# ESP32-C5 register map
Vendor: ESPRESSIF SYSTEMS (SHANGHAI) CO., LTD.; Series: ESP32 C-Series; File version: 1
CPU: RV32IMAC r0p0, little endian, no MPU, no FPU, 0 interrupt priority bits
Address unit: 32 bits
Registers are 32-bit, read-write, reset 0x0 unless marked. A register's access mark holds for its fields unless they carry their own. Offsets are from the block's base; [hi:lo] are bit positions; {n}, {i} and the like mark numbered series.

## PVT — PVT Peripheral
Base 0x60019000
{0x0+4i} PMUP_BITMAP_HIGH{i} (i=0..4) — select valid pvt channel
  [31:0] PUMP_BITMAP_HIGH{i} — select valid high channel{i}
{0x14+4i} PMUP_BITMAP_LOW{i} (i=0..4) — select valid pvt channel
  [31:0] PUMP_BITMAP_LOW{i} — select valid low channel{i}
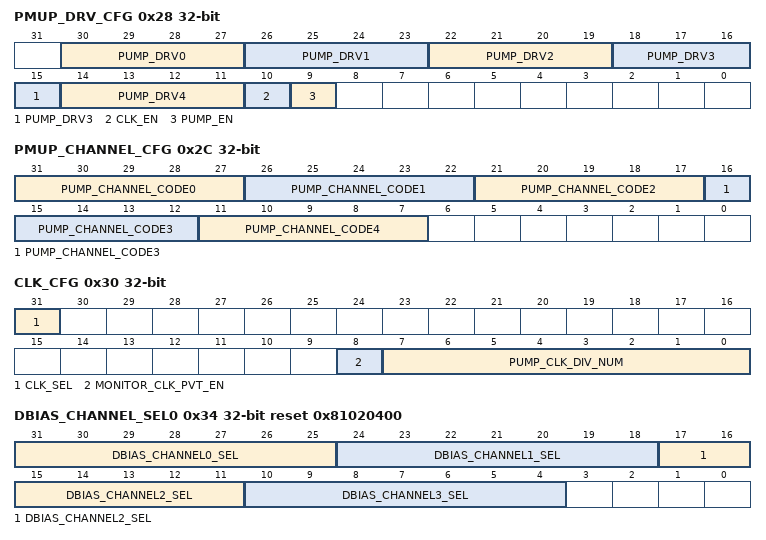
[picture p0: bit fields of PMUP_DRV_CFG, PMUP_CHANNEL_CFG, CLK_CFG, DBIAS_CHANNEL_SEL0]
0x28 PMUP_DRV_CFG — configure pump drv
  [30-4n:27-4n] PUMP_DRV{n} (n=0..4) — configure cmd{n} drv
  [10] CLK_EN — force register clken
  [9] PUMP_EN — configure pvt charge xpd
0x2C PMUP_CHANNEL_CFG — configure the code of valid pump channel code
  [31-5n:27-5n] PUMP_CHANNEL_CODE{n} (n=0..4) — configure cmd{n} code
0x30 CLK_CFG — configure pvt clk
  [31] CLK_SEL — select pvt clk
  [8] MONITOR_CLK_PVT_EN — needs field desc
  [7:0] PUMP_CLK_DIV_NUM — needs field desc
0x34 DBIAS_CHANNEL_SEL0 reset 0x81020400 — needs desc
  [31-7n:25-7n] DBIAS_CHANNEL{n}_SEL (n=0..3) — needs field desc
0x38 DBIAS_CHANNEL_SEL1 reset 0x80000000 — needs desc
  [31:25] DBIAS_CHANNEL4_SEL — needs field desc
{0x3C+4i} DBIAS_CHANNEL{i}_SEL (i=0..4) — needs desc
  [16:0] DBIAS_CHANNEL{i}_CFG — needs field desc
{0x50+4i} DBIAS_CMD{i} (i=0..4) — needs desc
  [16:0] DBIAS_CMD{i} — needs field desc
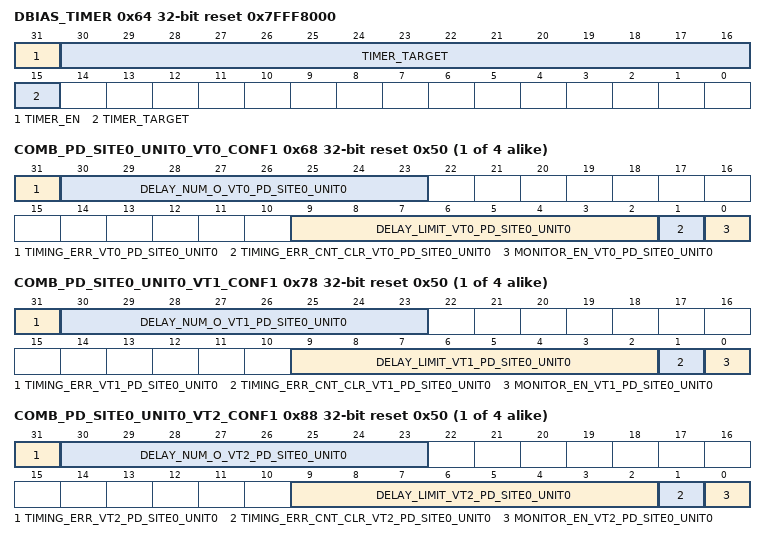
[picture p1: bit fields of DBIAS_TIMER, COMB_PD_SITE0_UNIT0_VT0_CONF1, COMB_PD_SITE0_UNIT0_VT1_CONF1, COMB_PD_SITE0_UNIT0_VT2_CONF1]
0x64 DBIAS_TIMER reset 0x7FFF8000 — needs desc
  [31] TIMER_EN — needs field desc
  [30:15] TIMER_TARGET — needs field desc
{0x68+4i} COMB_PD_SITE0_UNIT{i}_VT0_CONF1 ro reset 0x50 (i=0..3) — needs desc
  [31] TIMING_ERR_VT0_PD_SITE0_UNIT{i} — needs field desc
  [30:23] DELAY_NUM_O_VT0_PD_SITE0_UNIT{i} — needs field desc
  [9:2] DELAY_LIMIT_VT0_PD_SITE0_UNIT{i} — needs field desc
  [1] TIMING_ERR_CNT_CLR_VT0_PD_SITE0_UNIT{i} — needs field desc
  [0] MONITOR_EN_VT0_PD_SITE0_UNIT{i} — needs field desc
{0x78+4i} COMB_PD_SITE0_UNIT{i}_VT1_CONF1 ro reset 0x50 (i=0..3) — needs desc
  [31] TIMING_ERR_VT1_PD_SITE0_UNIT{i} — needs field desc
  [30:23] DELAY_NUM_O_VT1_PD_SITE0_UNIT{i} — needs field desc
  [9:2] DELAY_LIMIT_VT1_PD_SITE0_UNIT{i} — needs field desc
  [1] TIMING_ERR_CNT_CLR_VT1_PD_SITE0_UNIT{i} — needs field desc
  [0] MONITOR_EN_VT1_PD_SITE0_UNIT{i} — needs field desc
{0x88+4i} COMB_PD_SITE0_UNIT{i}_VT2_CONF1 ro reset 0x50 (i=0..3) — needs desc
  [31] TIMING_ERR_VT2_PD_SITE0_UNIT{i} — needs field desc
  [30:23] DELAY_NUM_O_VT2_PD_SITE0_UNIT{i} — needs field desc
  [9:2] DELAY_LIMIT_VT2_PD_SITE0_UNIT{i} — needs field desc
  [1] TIMING_ERR_CNT_CLR_VT2_PD_SITE0_UNIT{i} — needs field desc
  [0] MONITOR_EN_VT2_PD_SITE0_UNIT{i} — needs field desc
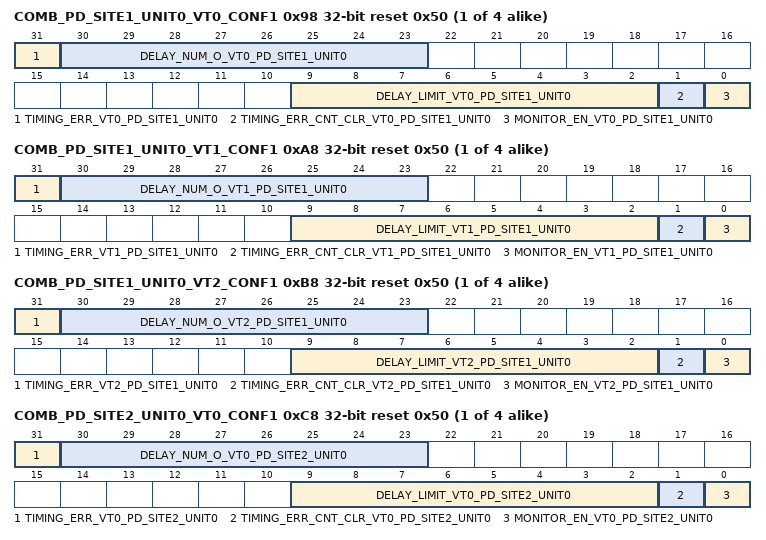
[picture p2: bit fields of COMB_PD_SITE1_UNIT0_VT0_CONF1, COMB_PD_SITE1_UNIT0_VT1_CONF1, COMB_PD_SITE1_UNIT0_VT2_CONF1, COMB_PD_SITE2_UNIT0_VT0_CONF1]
{0x98+4i} COMB_PD_SITE1_UNIT{i}_VT0_CONF1 ro reset 0x50 (i=0..3) — needs desc
  [31] TIMING_ERR_VT0_PD_SITE1_UNIT{i} — needs field desc
  [30:23] DELAY_NUM_O_VT0_PD_SITE1_UNIT{i} — needs field desc
  [9:2] DELAY_LIMIT_VT0_PD_SITE1_UNIT{i} — needs field desc
  [1] TIMING_ERR_CNT_CLR_VT0_PD_SITE1_UNIT{i} — needs field desc
  [0] MONITOR_EN_VT0_PD_SITE1_UNIT{i} — needs field desc
{0xA8+4i} COMB_PD_SITE1_UNIT{i}_VT1_CONF1 ro reset 0x50 (i=0..3) — needs desc
  [31] TIMING_ERR_VT1_PD_SITE1_UNIT{i} — needs field desc
  [30:23] DELAY_NUM_O_VT1_PD_SITE1_UNIT{i} — needs field desc
  [9:2] DELAY_LIMIT_VT1_PD_SITE1_UNIT{i} — needs field desc
  [1] TIMING_ERR_CNT_CLR_VT1_PD_SITE1_UNIT{i} — needs field desc
  [0] MONITOR_EN_VT1_PD_SITE1_UNIT{i} — needs field desc
{0xB8+4i} COMB_PD_SITE1_UNIT{i}_VT2_CONF1 ro reset 0x50 (i=0..3) — needs desc
  [31] TIMING_ERR_VT2_PD_SITE1_UNIT{i} — needs field desc
  [30:23] DELAY_NUM_O_VT2_PD_SITE1_UNIT{i} — needs field desc
  [9:2] DELAY_LIMIT_VT2_PD_SITE1_UNIT{i} — needs field desc
  [1] TIMING_ERR_CNT_CLR_VT2_PD_SITE1_UNIT{i} — needs field desc
  [0] MONITOR_EN_VT2_PD_SITE1_UNIT{i} — needs field desc
{0xC8+4i} COMB_PD_SITE2_UNIT{i}_VT0_CONF1 access per field reset 0x50 (i=0..3) — needs desc
  [31] TIMING_ERR_VT0_PD_SITE2_UNIT{i} ro — needs field desc
  [30:23] DELAY_NUM_O_VT0_PD_SITE2_UNIT{i} ro — needs field desc
  [9:2] DELAY_LIMIT_VT0_PD_SITE2_UNIT{i} rw — needs field desc
  [1] TIMING_ERR_CNT_CLR_VT0_PD_SITE2_UNIT{i} wo — needs field desc
  [0] MONITOR_EN_VT0_PD_SITE2_UNIT{i} rw — needs field desc
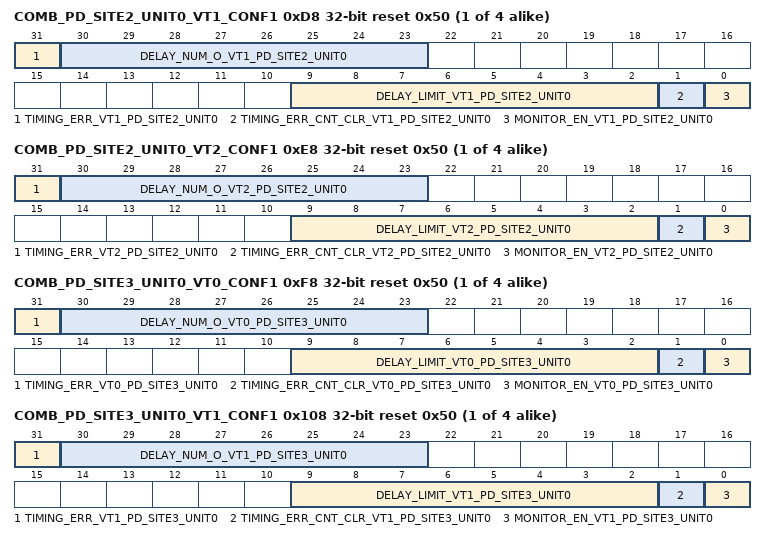
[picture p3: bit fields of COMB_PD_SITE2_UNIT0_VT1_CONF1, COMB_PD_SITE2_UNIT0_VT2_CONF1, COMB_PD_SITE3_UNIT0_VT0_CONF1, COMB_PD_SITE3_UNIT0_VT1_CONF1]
{0xD8+4i} COMB_PD_SITE2_UNIT{i}_VT1_CONF1 access per field reset 0x50 (i=0..3) — needs desc
  [31] TIMING_ERR_VT1_PD_SITE2_UNIT{i} ro — needs field desc
  [30:23] DELAY_NUM_O_VT1_PD_SITE2_UNIT{i} ro — needs field desc
  [9:2] DELAY_LIMIT_VT1_PD_SITE2_UNIT{i} rw — needs field desc
  [1] TIMING_ERR_CNT_CLR_VT1_PD_SITE2_UNIT{i} wo — needs field desc
  [0] MONITOR_EN_VT1_PD_SITE2_UNIT{i} rw — needs field desc
{0xE8+4i} COMB_PD_SITE2_UNIT{i}_VT2_CONF1 access per field reset 0x50 (i=0..3) — needs desc
  [31] TIMING_ERR_VT2_PD_SITE2_UNIT{i} ro — needs field desc
  [30:23] DELAY_NUM_O_VT2_PD_SITE2_UNIT{i} ro — needs field desc
  [9:2] DELAY_LIMIT_VT2_PD_SITE2_UNIT{i} rw — needs field desc
  [1] TIMING_ERR_CNT_CLR_VT2_PD_SITE2_UNIT{i} wo — needs field desc
  [0] MONITOR_EN_VT2_PD_SITE2_UNIT{i} rw — needs field desc
{0xF8+4i} COMB_PD_SITE3_UNIT{i}_VT0_CONF1 ro reset 0x50 (i=0..3) — needs desc
  [31] TIMING_ERR_VT0_PD_SITE3_UNIT{i} — needs field desc
  [30:23] DELAY_NUM_O_VT0_PD_SITE3_UNIT{i} — needs field desc
  [9:2] DELAY_LIMIT_VT0_PD_SITE3_UNIT{i} — needs field desc
  [1] TIMING_ERR_CNT_CLR_VT0_PD_SITE3_UNIT{i} — needs field desc
  [0] MONITOR_EN_VT0_PD_SITE3_UNIT{i} — needs field desc
{0x108+4i} COMB_PD_SITE3_UNIT{i}_VT1_CONF1 ro reset 0x50 (i=0..3) — needs desc
  [31] TIMING_ERR_VT1_PD_SITE3_UNIT{i} — needs field desc
  [30:23] DELAY_NUM_O_VT1_PD_SITE3_UNIT{i} — needs field desc
  [9:2] DELAY_LIMIT_VT1_PD_SITE3_UNIT{i} — needs field desc
  [1] TIMING_ERR_CNT_CLR_VT1_PD_SITE3_UNIT{i} — needs field desc
  [0] MONITOR_EN_VT1_PD_SITE3_UNIT{i} — needs field desc
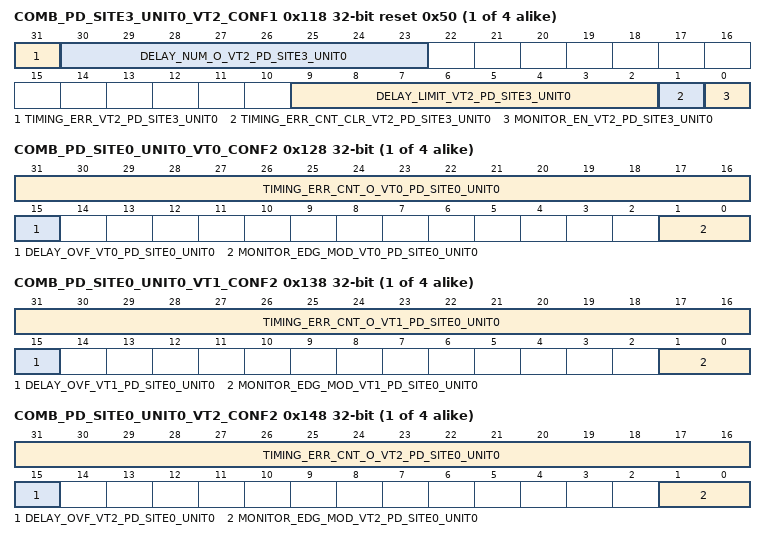
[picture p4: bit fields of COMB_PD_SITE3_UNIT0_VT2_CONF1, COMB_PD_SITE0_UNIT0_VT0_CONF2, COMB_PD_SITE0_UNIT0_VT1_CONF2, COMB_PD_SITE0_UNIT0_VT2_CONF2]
{0x118+4i} COMB_PD_SITE3_UNIT{i}_VT2_CONF1 ro reset 0x50 (i=0..3) — needs desc
  [31] TIMING_ERR_VT2_PD_SITE3_UNIT{i} — needs field desc
  [30:23] DELAY_NUM_O_VT2_PD_SITE3_UNIT{i} — needs field desc
  [9:2] DELAY_LIMIT_VT2_PD_SITE3_UNIT{i} — needs field desc
  [1] TIMING_ERR_CNT_CLR_VT2_PD_SITE3_UNIT{i} — needs field desc
  [0] MONITOR_EN_VT2_PD_SITE3_UNIT{i} — needs field desc
{0x128+4i} COMB_PD_SITE0_UNIT{i}_VT0_CONF2 ro (i=0..3) — needs desc
  [31:16] TIMING_ERR_CNT_O_VT0_PD_SITE0_UNIT{i} — needs field desc
  [15] DELAY_OVF_VT0_PD_SITE0_UNIT{i} — needs field desc
  [1:0] MONITOR_EDG_MOD_VT0_PD_SITE0_UNIT{i} — needs field desc
{0x138+4i} COMB_PD_SITE0_UNIT{i}_VT1_CONF2 ro (i=0..3) — needs desc
  [31:16] TIMING_ERR_CNT_O_VT1_PD_SITE0_UNIT{i} — needs field desc
  [15] DELAY_OVF_VT1_PD_SITE0_UNIT{i} — needs field desc
  [1:0] MONITOR_EDG_MOD_VT1_PD_SITE0_UNIT{i} — needs field desc
{0x148+4i} COMB_PD_SITE0_UNIT{i}_VT2_CONF2 ro (i=0..3) — needs desc
  [31:16] TIMING_ERR_CNT_O_VT2_PD_SITE0_UNIT{i} — needs field desc
  [15] DELAY_OVF_VT2_PD_SITE0_UNIT{i} — needs field desc
  [1:0] MONITOR_EDG_MOD_VT2_PD_SITE0_UNIT{i} — needs field desc
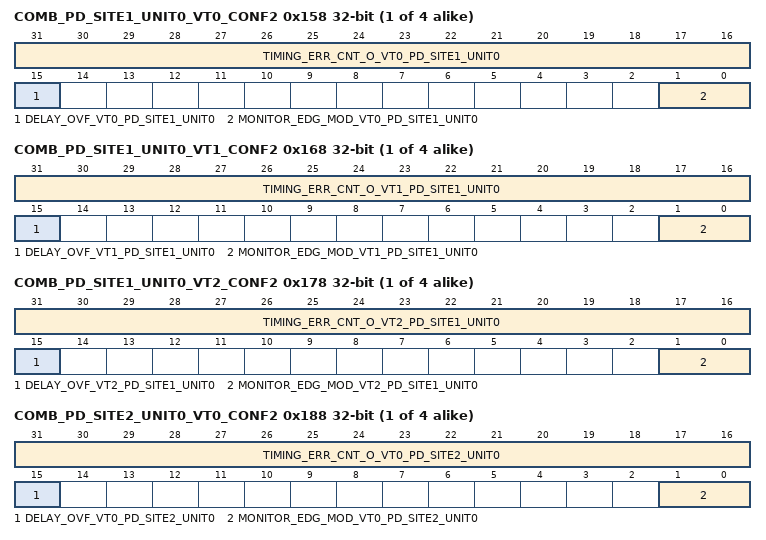
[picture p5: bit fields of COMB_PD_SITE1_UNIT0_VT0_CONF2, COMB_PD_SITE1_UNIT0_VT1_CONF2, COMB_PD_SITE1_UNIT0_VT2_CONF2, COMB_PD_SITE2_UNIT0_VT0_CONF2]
{0x158+4i} COMB_PD_SITE1_UNIT{i}_VT0_CONF2 ro (i=0..3) — needs desc
  [31:16] TIMING_ERR_CNT_O_VT0_PD_SITE1_UNIT{i} — needs field desc
  [15] DELAY_OVF_VT0_PD_SITE1_UNIT{i} — needs field desc
  [1:0] MONITOR_EDG_MOD_VT0_PD_SITE1_UNIT{i} — needs field desc
{0x168+4i} COMB_PD_SITE1_UNIT{i}_VT1_CONF2 ro (i=0..3) — needs desc
  [31:16] TIMING_ERR_CNT_O_VT1_PD_SITE1_UNIT{i} — needs field desc
  [15] DELAY_OVF_VT1_PD_SITE1_UNIT{i} — needs field desc
  [1:0] MONITOR_EDG_MOD_VT1_PD_SITE1_UNIT{i} — needs field desc
{0x178+4i} COMB_PD_SITE1_UNIT{i}_VT2_CONF2 ro (i=0..3) — needs desc
  [31:16] TIMING_ERR_CNT_O_VT2_PD_SITE1_UNIT{i} — needs field desc
  [15] DELAY_OVF_VT2_PD_SITE1_UNIT{i} — needs field desc
  [1:0] MONITOR_EDG_MOD_VT2_PD_SITE1_UNIT{i} — needs field desc
{0x188+4i} COMB_PD_SITE2_UNIT{i}_VT0_CONF2 access per field (i=0..3) — needs desc
  [31:16] TIMING_ERR_CNT_O_VT0_PD_SITE2_UNIT{i} ro — needs field desc
  [15] DELAY_OVF_VT0_PD_SITE2_UNIT{i} ro — needs field desc
  [1:0] MONITOR_EDG_MOD_VT0_PD_SITE2_UNIT{i} rw — needs field desc
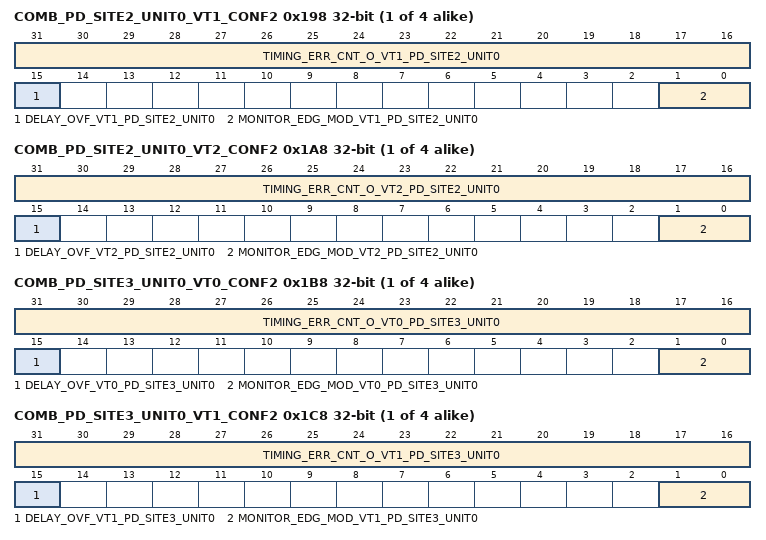
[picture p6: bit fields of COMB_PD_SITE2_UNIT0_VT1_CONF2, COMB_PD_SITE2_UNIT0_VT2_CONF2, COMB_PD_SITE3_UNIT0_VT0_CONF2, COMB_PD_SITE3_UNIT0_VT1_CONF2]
{0x198+4i} COMB_PD_SITE2_UNIT{i}_VT1_CONF2 access per field (i=0..3) — needs desc
  [31:16] TIMING_ERR_CNT_O_VT1_PD_SITE2_UNIT{i} ro — needs field desc
  [15] DELAY_OVF_VT1_PD_SITE2_UNIT{i} ro — needs field desc
  [1:0] MONITOR_EDG_MOD_VT1_PD_SITE2_UNIT{i} rw — needs field desc
{0x1A8+4i} COMB_PD_SITE2_UNIT{i}_VT2_CONF2 access per field (i=0..3) — needs desc
  [31:16] TIMING_ERR_CNT_O_VT2_PD_SITE2_UNIT{i} ro — needs field desc
  [15] DELAY_OVF_VT2_PD_SITE2_UNIT{i} ro — needs field desc
  [1:0] MONITOR_EDG_MOD_VT2_PD_SITE2_UNIT{i} rw — needs field desc
{0x1B8+4i} COMB_PD_SITE3_UNIT{i}_VT0_CONF2 access per field (i=0..3) — needs desc
  [31:16] TIMING_ERR_CNT_O_VT0_PD_SITE3_UNIT{i} ro — needs field desc
  [15] DELAY_OVF_VT0_PD_SITE3_UNIT{i} ro — needs field desc
  [1:0] MONITOR_EDG_MOD_VT0_PD_SITE3_UNIT{i} rw — needs field desc
{0x1C8+4i} COMB_PD_SITE3_UNIT{i}_VT1_CONF2 access per field (i=0..3) — needs desc
  [31:16] TIMING_ERR_CNT_O_VT1_PD_SITE3_UNIT{i} ro — needs field desc
  [15] DELAY_OVF_VT1_PD_SITE3_UNIT{i} ro — needs field desc
  [1:0] MONITOR_EDG_MOD_VT1_PD_SITE3_UNIT{i} rw — needs field desc
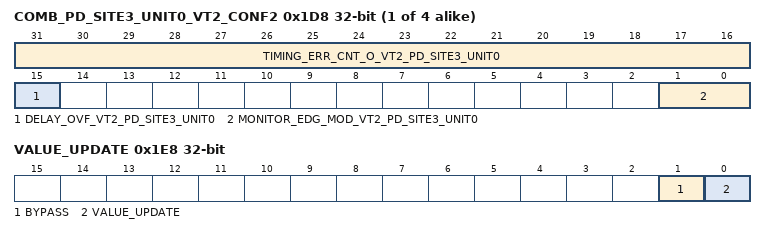
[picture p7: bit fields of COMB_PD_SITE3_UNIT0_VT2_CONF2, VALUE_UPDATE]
{0x1D8+4i} COMB_PD_SITE3_UNIT{i}_VT2_CONF2 access per field (i=0..3) — needs desc
  [31:16] TIMING_ERR_CNT_O_VT2_PD_SITE3_UNIT{i} ro — needs field desc
  [15] DELAY_OVF_VT2_PD_SITE3_UNIT{i} ro — needs field desc
  [1:0] MONITOR_EDG_MOD_VT2_PD_SITE3_UNIT{i} rw — needs field desc
0x1E8 VALUE_UPDATE access per field — needs field desc
  [1] BYPASS rw — needs field desc
  [0] VALUE_UPDATE wo — needs field desc
0x1EC BYPASS_CHAIN reset 0xFFFFFFFF — needs field desc
  [31:0] CLK_CHAIN_EN
0xFFC DATE reset 0x2112130 — version register
